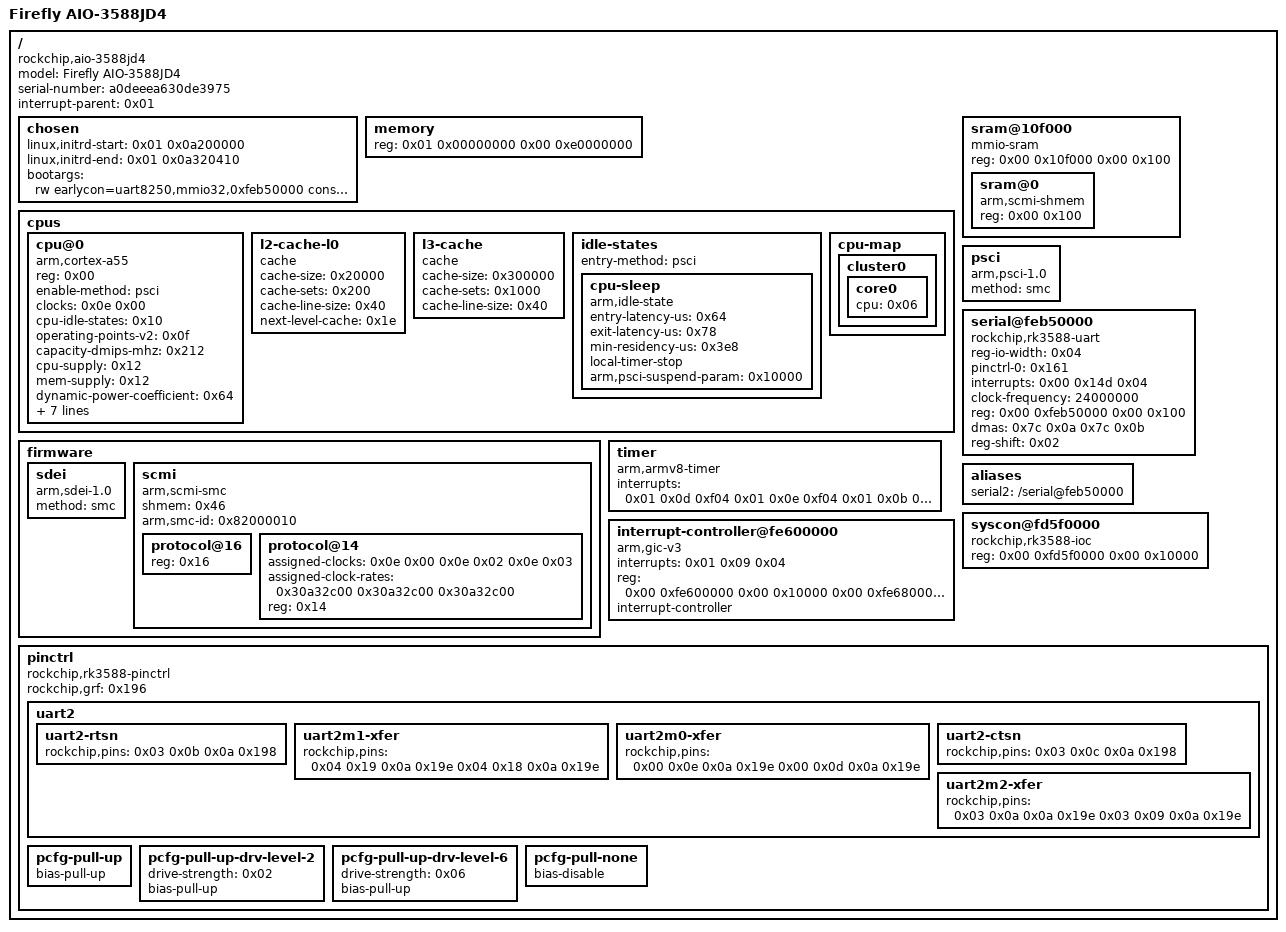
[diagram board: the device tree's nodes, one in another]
/dts-v1/;

/ {
	#address-cells = <0x02>;
	model = "Firefly AIO-3588JD4";
	serial-number = "a0deeea630de3975";
	#size-cells = <0x02>;
	interrupt-parent = <0x01>;
	compatible = "rockchip,aio-3588jd4\0rockchip,rk3588";

	chosen {
		linux,initrd-start = <0x01 0x0a200000>;
		linux,initrd-end = <0x01 0x0a320410>;
		bootargs = "rw earlycon=uart8250,mmio32,0xfeb50000 console=ttyS2,115200n8 irqchip.gicv3_pseudo_nmi=0 initcall_debug";
		phandle = <0x48d>;
	};

	memory {
		device_type = "memory";
		reg = <0x01 0x00000000 0x00 0xe0000000 >;
	};

	cpus {
		#address-cells = <0x01>;
		#size-cells = <0x00>;

		cpu@0 {
			device_type = "cpu";
			compatible = "arm,cortex-a55";
			reg = <0x00>;
			enable-method = "psci";
			clocks = <0x0e 0x00>;
			cpu-idle-states = <0x10>;
			operating-points-v2 = <0x0f>;
			capacity-dmips-mhz = <0x212>;

			cpu-supply = <0x12>;
			mem-supply = <0x12>;
			dynamic-power-coefficient = <0x64>;

			i-cache-line-size = <0x40>;
			i-cache-size = <0x8000>;
			i-cache-sets = <0x80>;

			d-cache-line-size = <0x40>;
			d-cache-size = <0x8000>;
			d-cache-sets = <0x80>;

			next-level-cache = <0x11>;
			#cooling-cells = <0x02>;
			phandle = <0x06>;
		};

		l2-cache-l0 {
			compatible = "cache";
			cache-size = <0x20000>;
			cache-sets = <0x200>;
			cache-line-size = <0x40>;
			next-level-cache = <0x1e>;
			phandle = <0x11>;
		};

		l3-cache {
			compatible = "cache";
			cache-size = <0x300000>;
			cache-sets = <0x1000>;
			cache-line-size = <0x40>;
			phandle = <0x1e>;
		};

		idle-states {
			entry-method = "psci";

			cpu-sleep {
				compatible = "arm,idle-state";
				entry-latency-us = <0x64>;
				exit-latency-us = <0x78>;
				min-residency-us = <0x3e8>;
				local-timer-stop;
				arm,psci-suspend-param = <0x10000>;
				phandle = <0x10>;
			};
		};

		cpu-map {
			cluster0 {
				core0 {
					cpu = <0x06>;
				};
			};
		};
	};

	sram@10f000 {
		#address-cells = <0x01>;
		#size-cells = <0x01>;
		compatible = "mmio-sram";
		ranges = <0x00 0x00 0x10f000 0x100>;
		reg = <0x00 0x10f000 0x00 0x100>;

		sram@0 {
			compatible = "arm,scmi-shmem";
			reg = <0x00 0x100>;
			phandle = <0x46>;
		};
	};

	firmware {
		sdei {
			method = "smc";
			compatible = "arm,sdei-1.0";
			phandle = <0x221>;
		};

		scmi {
			shmem = <0x46>;
			#address-cells = <0x01>;
			#size-cells = <0x00>;
			compatible = "arm,scmi-smc";
			phandle = <0x220>;
			arm,smc-id = <0x82000010>;

			protocol@16 {
				#reset-cells = <0x01>;
				reg = <0x16>;
				phandle = <0x11a>;
			};

			protocol@14 {
				assigned-clocks = <0x0e 0x00 0x0e 0x02 0x0e 0x03>;
				assigned-clock-rates = <0x30a32c00 0x30a32c00 0x30a32c00>;
				#clock-cells = <0x01>;
				reg = <0x14>;
				phandle = <0x0e>;
			};
		};
	};

	timer {
		interrupts = <0x01 0x0d 0xf04 0x01 0x0e 0xf04 0x01 0x0b 0xf04 0x01 0x0a 0xf04>;
		compatible = "arm,armv8-timer";
	};

	interrupt-controller@fe600000 {
		#address-cells = <0x02>;
		interrupts = <0x01 0x09 0x04>;
		#size-cells = <0x02>;
		compatible = "arm,gic-v3";
		ranges;
		#interrupt-cells = <0x03>;
		reg = <0x00 0xfe600000 0x00 0x10000 0x00 0xfe680000 0x00 0x100000>;
		phandle = <0x01>;
		interrupt-controller;

	};

	psci {
		method = "smc";
		compatible = "arm,psci-1.0";
	};

	serial@feb50000 {
		reg-io-width = <0x04>;
		pinctrl-names = "default";
		pinctrl-0 = <0x161>;
		interrupts = <0x00 0x14d 0x04>;
		// Avoid driver messing with CRU
		clock-frequency = <24000000>;
		// clock-names = "baudclk\0apb_pclk";
		// clocks = <0x02 0xbb 0x02 0xac>;
		compatible = "rockchip,rk3588-uart\0snps,dw-apb-uart";
		status = "okay";
		reg = <0x00 0xfeb50000 0x00 0x100>;
		phandle = <0x2ca>;
		dmas = <0x7c 0x0a 0x7c 0x0b>;
		reg-shift = <0x02>;
	};

	aliases {
		serial2 = "/serial@feb50000";
	};

	__symbols__ {
		chosen = "/chosen";
		gic = "/interrupt-controller@fe600000";
		uart2 = "/serial@feb50000";

		scmi_shmem = "/sram@10f000/sram@0";
		scmi = "/firmware/scmi";
		scmi_reset = "/firmware/scmi/protocol@16";
		scmi_clk = "/firmware/scmi/protocol@14";
	};

	syscon@fd5f0000 {
		compatible = "rockchip,rk3588-ioc\0syscon";
		reg = <0x00 0xfd5f0000 0x00 0x10000>;
		phandle = <0x196>;
	};

	pinctrl {
		#address-cells = <0x02>;
		#size-cells = <0x02>;
		compatible = "rockchip,rk3588-pinctrl";
		ranges;
		rockchip,grf = <0x196>;
		phandle = <0x197>;

		uart2 {

			uart2-rtsn {
				rockchip,pins = <0x03 0x0b 0x0a 0x198>;
				phandle = <0x427>;
			};

			uart2m1-xfer {
				rockchip,pins = <0x04 0x19 0x0a 0x19e 0x04 0x18 0x0a 0x19e>;
				phandle = <0x161>;
			};

			uart2m0-xfer {
				rockchip,pins = <0x00 0x0e 0x0a 0x19e 0x00 0x0d 0x0a 0x19e>;
				phandle = <0x1ce>;
			};

			uart2-ctsn {
				rockchip,pins = <0x03 0x0c 0x0a 0x198>;
				phandle = <0x426>;
			};

			uart2m2-xfer {
				rockchip,pins = <0x03 0x0a 0x0a 0x19e 0x03 0x09 0x0a 0x19e>;
				phandle = <0x425>;
			};
		};

		// output

		// pull up

		pcfg-pull-up {
			phandle = <0x19e>;
			bias-pull-up;
		};

		pcfg-pull-up-drv-level-2 {
			drive-strength = <0x02>;
			phandle = <0x199>;
			bias-pull-up;
		};

		pcfg-pull-up-drv-level-6 {
			drive-strength = <0x06>;
			phandle = <0x19a>;
			bias-pull-up;
		};

		// pull down

		// pull none

		pcfg-pull-none {
			bias-disable;
			phandle = <0x198>;
		};
	};

};
